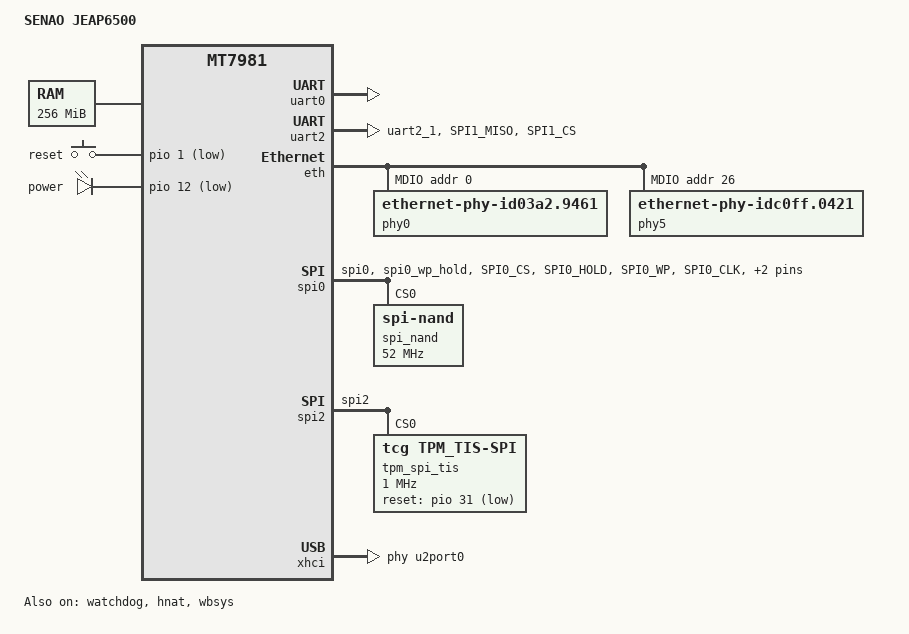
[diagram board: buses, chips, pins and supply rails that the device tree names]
/dts-v1/;
#include "mt7981.dtsi"
/ {
	model = "SENAO JEAP6500";
	compatible = "senao,jeap6500";
	chosen {
		bootargs = "console=ttyS0,115200n1 loglevel=8  \
				earlycon=uart8250,mmio32,0x11002000";
	};

	memory {
		reg = <0 0x40000000 0 0x10000000>;
	};

	gpio-keys {
		compatible = "gpio-keys";

		reset {
			label = "reset";
			linux,code = <KEY_RESTART>;
			gpios = <&pio 1 GPIO_ACTIVE_LOW>;
		};
	};

	nmbm_spim_nand {
		compatible = "generic,nmbm";

		#address-cells = <1>;
		#size-cells = <1>;

		lower-mtd-device = <&spi_nand>;
		forced-create;

		partitions {
			compatible = "fixed-partitions";
			#address-cells = <1>;
			#size-cells = <1>;

			partition@0 {
				label = "BL2";
				reg = <0x00000 0x0100000>;
				read-only;
			};

			partition@100000 {
				label = "u-boot-env";
				reg = <0x0100000 0x0080000>;
			};

			factory: partition@180000 {
				label = "Factory";
				reg = <0x180000 0x0200000>;
			};

			partition@380000 {
				label = "FIP";
				reg = <0x380000 0x0200000>;
			};

			partition@580000 {
				label = "ubi";
				reg = <0x580000 0x6E00000>;
			};

			partition@7380000 {
				label = "ubi_1";
				reg = <0x7380000 0x6E00000>;
			};

			partition@E180000 {
				label = "cert";
				reg = <0xE180000 0x0060000>;
			};

			partition@E1E0000 {
				label = "userconfig";
				reg = <0xE1E0000 0x00a0000>;
			};

			partition@E280000 {
				label = "crashdump";
				reg = <0xE280000 0x0060000>;
			};
		};
	};

	sound_wm8960 {
		compatible = "mediatek,mt79xx-wm8960-machine";
		mediatek,platform = <&afe>;
		audio-routing = "Headphone", "HP_L",
				"Headphone", "HP_R",
				"LINPUT1", "AMIC",
				"RINPUT1", "AMIC";
		mediatek,audio-codec = <&wm8960>;
		status = "disabled";
	};

	sound_si3218x {
		compatible = "mediatek,mt79xx-si3218x-machine";
		mediatek,platform = <&afe>;
		mediatek,ext-codec = <&proslic_spi>;
		status = "disabled";
	};

	leds {
		compatible = "gpio-leds";
		power {
			label = "power";
			gpios = <&pio 12 GPIO_ACTIVE_LOW>;
			drive-strength = <MTK_DRIVE_16mA>;
			default-state = "on";
		};
	};
};

&afe {
	pinctrl-names = "default";
	pinctrl-0 = <&pcm_pins>;
	status = "disabled";
};

&i2c0 {
	pinctrl-names = "default";
	pinctrl-0 = <&i2c_pins>;
	status = "disabled";

	wm8960: wm8960@1a {
		compatible = "wlf,wm8960";
		reg = <0x1a>;
	};
};

&uart0 {
	status = "okay";
};

&uart2 {
	pinctrl-names = "default";
	pinctrl-0 = <&uart2_pins>;
	status = "okay";
};

&watchdog {
	status = "okay";
};

&eth {
        status = "okay";

        gmac0: mac@0 {
                compatible = "mediatek,eth-mac";
                reg = <0>;
                phy-mode = "sgmii";
                phy-handle = <&phy5>;
        };

	gmac1: mac@1 {
		compatible = "mediatek,eth-mac";
		reg = <1>;
		phy-mode = "gmii";
		phy-handle = <&phy0>;
	};

        mdio: mdio-bus {
                #address-cells = <1>;
                #size-cells = <0>;
		reset-gpios = <&pio 39 1>;

		phy0: ethernet-phy@0 {
			compatible = "ethernet-phy-id03a2.9461";
			reg = <0>;
			phy-mode = "gmii";
			nvmem-cells = <&phy_calibration>;
			nvmem-cell-names = "phy-cal-data";
		};

		phy5: phy@5 {
			compatible = "ethernet-phy-idc0ff.0421";
			reg = <26>;
			phy-mode = "sgmii";
			full-duplex;
			pause;
			airoha,polarity = <2>;
		};
        };
};

&hnat {
	mtketh-wan = "eth0";
	mtketh-lan = "eth1";
	mtketh-max-gmac = <2>;
	status = "okay";
};

&spi0 {
	pinctrl-names = "default";
	pinctrl-0 = <&spi0_flash_pins>;
	status = "okay";
	spi_nand: spi_nand@0 {
		#address-cells = <1>;
		#size-cells = <1>;
		compatible = "spi-nand";
		reg = <0>;
		spi-max-frequency = <52000000>;
		spi-tx-bus-width = <4>;
		spi-rx-bus-width = <4>;
	};
};

&spi1 {
	pinctrl-names = "default";
	pinctrl-0 = <&spic_pins>;
	status = "disabled";

	proslic_spi: proslic_spi@0 {
		compatible = "silabs,proslic_spi";
		reg = <0>;
		spi-max-frequency = <10000000>;
		spi-cpha = <1>;
		spi-cpol = <1>;
		channel_count = <1>;
		debug_level = <4>;       /* 1 = TRC, 2 = DBG, 4 = ERR */
		reset_gpio = <&pio 15 0>;
		ig,enable-spi = <1>;     /* 1: Enable, 0: Disable */
	};
};

&wbsys {
	mediatek,mtd-eeprom = <&factory 0x0000>;
	status = "okay";
	pinctrl-names = "dbdc";
	pinctrl-0 = <&wf_dbdc_pins>;
};

&spi2 {
	pinctrl-names = "default";
	pinctrl-0 = <&spi2_pins>;
	status = "okay";

	tpm_spi_tis@0 {
		compatible = "tcg,tpm_tis-spi";
		reg = <0>;
		#address-cells = <1>;
		#size-cells = <1>;
		spi-max-frequency = <1000000>;
		spi-tx-buswidth = <4>;
		spi-rx-buswidth = <4>;
		reset-gpios = <&pio 31 1>;
	};
};

&pio {

	i2c_pins: i2c-pins-g0 {
                mux {
                        function = "i2c";
                        groups = "i2c0_0";
                };
        };

        pcm_pins: pcm-pins-g0 {
                mux {
                        function = "pcm";
                        groups = "pcm";
                };
        };

        pwm0_pin: pwm0-pin-g0 {
                mux {
                        function = "pwm";
                        groups = "pwm0_0";
                };
        };

        pwm1_pin: pwm1-pin-g0 {
                mux {
                        function = "pwm";
                        groups = "pwm1_0";
                };
        };

        pwm2_pin: pwm2-pin {
                mux {
                        function = "pwm";
                        groups = "pwm2";
                };
        };

	spi0_flash_pins: spi0-pins {
		mux {
			function = "spi";
			groups = "spi0", "spi0_wp_hold";
		};

		conf-pu {
			pins = "SPI0_CS", "SPI0_HOLD", "SPI0_WP";
			drive-strength = <MTK_DRIVE_8mA>;
			bias-pull-up = <MTK_PUPD_SET_R1R0_11>;
		};

		conf-pd {
			pins = "SPI0_CLK", "SPI0_MOSI", "SPI0_MISO";
			drive-strength = <MTK_DRIVE_8mA>;
			bias-pull-down = <MTK_PUPD_SET_R1R0_11>;
		};
	};

	spic_pins: spi1-pins {
		mux {
			function = "spi";
			groups = "spi1_1";
		};
	};

	spi2_pins: spi2-pins {
		mux {
			function = "spi";
			groups = "spi2";
		};
	};

	uart1_pins: uart1-pins-g1 {
                mux {
                        function = "uart";
                        groups = "uart1_1";
                };
        };

	uart2_pins: uart2-pins-g1 {
		mux {
                        function = "uart";
                        groups = "uart2_1";
                };
		ble_loader {
			pins = "SPI1_MISO";
			function = "gpio";
			drive-strength = <MTK_DRIVE_8mA>;
			bias-pull-up = <MTK_PUPD_SET_R1R0_11>;
			output-high;
		};
		ble_reset {
			pins = "SPI1_CS";
			function = "gpio";
			drive-strength = <MTK_DRIVE_8mA>;
			bias-pull-up = <MTK_PUPD_SET_R1R0_11>;
			output-high;
		};
        };

	wf_dbdc_pins: wf_dbdc-pins {
		mux {
			function = "eth";
			groups = "wf0_mode1";
		};
		conf {
			pins = "WF_HB1", "WF_HB2", "WF_HB3", "WF_HB4",
			       "WF_HB0", "WF_HB0_B", "WF_HB5", "WF_HB6",
			       "WF_HB7", "WF_HB8", "WF_HB9", "WF_HB10",
			       "WF_TOP_CLK", "WF_TOP_DATA", "WF_XO_REQ",
			       "WF_CBA_RESETB", "WF_DIG_RESETB";
			drive-strength = <MTK_DRIVE_4mA>;
		};
	};

	pta_pins: pta-pins {
		mux {
			function = "pta";
			groups = "pta_ext_0";
		};
	};
};

&xhci {
	mediatek,u3p-dis-msk = <0x0>;
	phys = <&u2port0 PHY_TYPE_USB2>,
	       <&u3port0 PHY_TYPE_USB3>;
	status = "okay";
};
